AUTOSAR XML (schema 4-2-2)
package /ComponentTypes
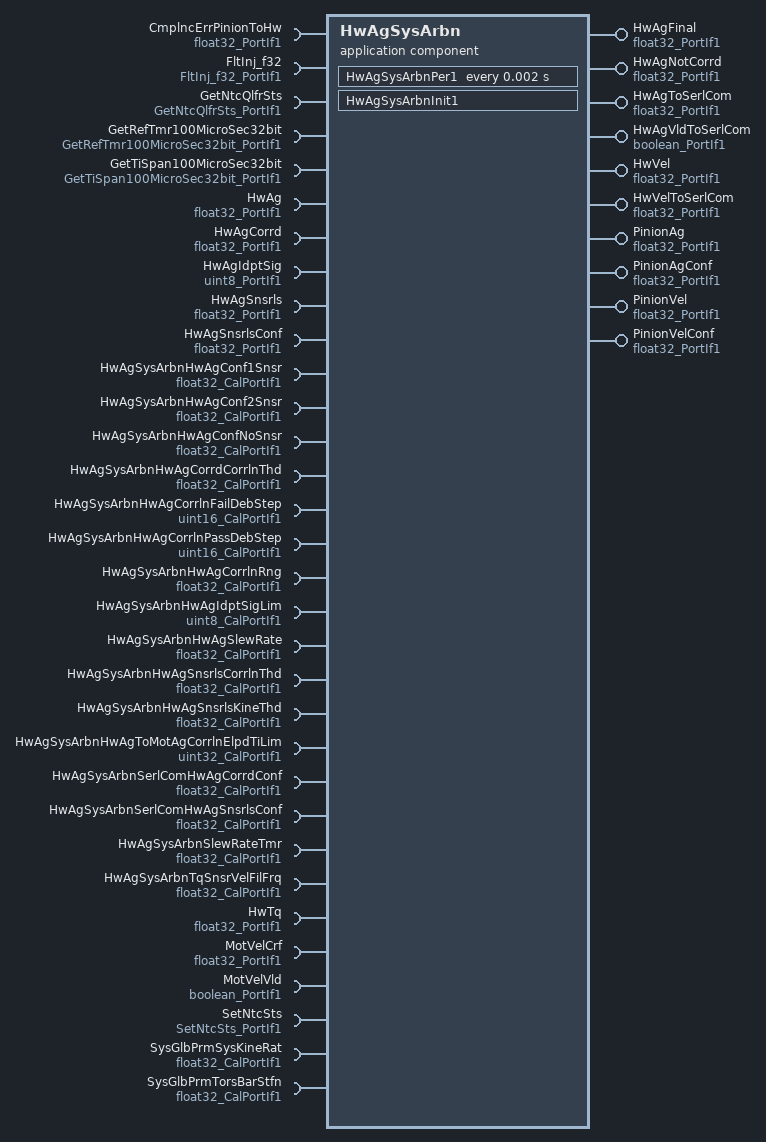
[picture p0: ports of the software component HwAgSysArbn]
  application sw component type HwAgSysArbn
    10 x provide port:
      HwAgFinal: nonqueued-sender-com-spec{data-element=Val, init-value=0}, provided-interface=float32_PortIf1
      HwAgNotCorrd: nonqueued-sender-com-spec{data-element=Val, init-value=0}, provided-interface=float32_PortIf1
      HwAgToSerlCom: nonqueued-sender-com-spec{data-element=Val, init-value=0}, provided-interface=float32_PortIf1
      HwAgVldToSerlCom: nonqueued-sender-com-spec{data-element=Logl, init-value=0}, provided-interface=boolean_PortIf1
      HwVel: nonqueued-sender-com-spec{data-element=Val, init-value=0}, provided-interface=float32_PortIf1
      HwVelToSerlCom: nonqueued-sender-com-spec{data-element=Val, init-value=0}, provided-interface=float32_PortIf1
      PinionAg: nonqueued-sender-com-spec{data-element=Val, init-value=0}, provided-interface=float32_PortIf1
      PinionAgConf: nonqueued-sender-com-spec{data-element=Val, init-value=0}, provided-interface=float32_PortIf1
      PinionVel: nonqueued-sender-com-spec{data-element=Val, init-value=0}, provided-interface=float32_PortIf1
      PinionVelConf: nonqueued-sender-com-spec{data-element=Val, init-value=0}, provided-interface=float32_PortIf1
    32 x require port:
      CmplncErrPinionToHw: nonqueued-receiver-com-spec{data-element=Val, filter=data-filter-type=ALWAYS, init-value=0}, required-interface=float32_PortIf1
      FltInj_f32: client-com-spec=Oper, required-interface=FltInj_f32_PortIf1
      GetNtcQlfrSts: client-com-spec=Oper, required-interface=GetNtcQlfrSts_PortIf1
      GetRefTmr100MicroSec32bit: client-com-spec=Oper, required-interface=GetRefTmr100MicroSec32bit_PortIf1
      GetTiSpan100MicroSec32bit: client-com-spec=Oper, required-interface=GetTiSpan100MicroSec32bit_PortIf1
      HwAg: nonqueued-receiver-com-spec{data-element=Val, filter=data-filter-type=ALWAYS, init-value=0}, required-interface=float32_PortIf1
      HwAgCorrd: nonqueued-receiver-com-spec{data-element=Val, filter=data-filter-type=ALWAYS, init-value=0}, required-interface=float32_PortIf1
      HwAgIdptSig: nonqueued-receiver-com-spec{data-element=Val, filter=data-filter-type=ALWAYS, init-value=2}, required-interface=uint8_PortIf1
      HwAgSnsrls: nonqueued-receiver-com-spec{data-element=Val, filter=data-filter-type=ALWAYS, init-value=0}, required-interface=float32_PortIf1
      HwAgSnsrlsConf: nonqueued-receiver-com-spec{data-element=Val, filter=data-filter-type=ALWAYS, init-value=0}, required-interface=float32_PortIf1
      HwAgSysArbnHwAgConf1Snsr: parameter-require-com-spec{init-value=1, parameter=Val}, required-interface=float32_CalPortIf1
      HwAgSysArbnHwAgConf2Snsr: parameter-require-com-spec{init-value=1, parameter=Val}, required-interface=float32_CalPortIf1
      HwAgSysArbnHwAgConfNoSnsr: parameter-require-com-spec{init-value=0, parameter=Val}, required-interface=float32_CalPortIf1
      HwAgSysArbnHwAgCorrdCorrlnThd: parameter-require-com-spec{init-value=1, parameter=Val}, required-interface=float32_CalPortIf1
      HwAgSysArbnHwAgCorrlnFailDebStep: parameter-require-com-spec{init-value=132, parameter=Val}, required-interface=uint16_CalPortIf1
      HwAgSysArbnHwAgCorrlnPassDebStep: parameter-require-com-spec{init-value=132, parameter=Val}, required-interface=uint16_CalPortIf1
      HwAgSysArbnHwAgCorrlnRng: parameter-require-com-spec{init-value=5, parameter=Val}, required-interface=float32_CalPortIf1
      HwAgSysArbnHwAgIdptSigLim: parameter-require-com-spec{init-value=1, parameter=Val}, required-interface=uint8_CalPortIf1
      HwAgSysArbnHwAgSlewRate: parameter-require-com-spec{init-value=100, parameter=Val}, required-interface=float32_CalPortIf1
      HwAgSysArbnHwAgSnsrlsCorrlnThd: parameter-require-com-spec{init-value=1, parameter=Val}, required-interface=float32_CalPortIf1
      HwAgSysArbnHwAgSnsrlsKineThd: parameter-require-com-spec{init-value=1500, parameter=Val}, required-interface=float32_CalPortIf1
      HwAgSysArbnHwAgToMotAgCorrlnElpdTiLim: parameter-require-com-spec{init-value=86400, parameter=Val}, required-interface=uint32_CalPortIf1
      HwAgSysArbnSerlComHwAgCorrdConf: parameter-require-com-spec{init-value=1, parameter=Val}, required-interface=float32_CalPortIf1
      HwAgSysArbnSerlComHwAgSnsrlsConf: parameter-require-com-spec{init-value=1, parameter=Val}, required-interface=float32_CalPortIf1
      HwAgSysArbnSlewRateTmr: parameter-require-com-spec{init-value=1000, parameter=Val}, required-interface=float32_CalPortIf1
      HwAgSysArbnTqSnsrVelFilFrq: parameter-require-com-spec{init-value=20, parameter=Val}, required-interface=float32_CalPortIf1
      HwTq: nonqueued-receiver-com-spec{data-element=Val, filter=data-filter-type=ALWAYS, init-value=0}, required-interface=float32_PortIf1
      MotVelCrf: nonqueued-receiver-com-spec{data-element=Val, filter=data-filter-type=ALWAYS, init-value=0}, required-interface=float32_PortIf1
      MotVelVld: nonqueued-receiver-com-spec{data-element=Logl, filter=data-filter-type=ALWAYS, init-value=0}, required-interface=boolean_PortIf1
      SetNtcSts: client-com-spec=Oper, required-interface=SetNtcSts_PortIf1
      SysGlbPrmSysKineRat: parameter-require-com-spec{init-value=22, parameter=Val}, required-interface=float32_CalPortIf1
      SysGlbPrmTorsBarStfn: parameter-require-com-spec{init-value=2.5, parameter=Val}, required-interface=float32_CalPortIf1
    behavior HwAgSysArbn_InternalBehavior
      ar-typed-per-instance-memorys:
        14 x data, all with sw-calibration-access=READ-ONLY:
          HwAgKineFlt: type=boolean
          HwAgLtch: type=boolean
          HwAgPrev: type=float32
          HwAgToMotAgCorrln: type=boolean
          HwAgToMotAgCorrlnDurnRefTmr: type=uint32
          PrevHwAgNotCorrd: type=float32
          PrevPinionAgConf: type=float32
          PrevSeldHwAg: type=float32
          PrevSrcSeln: type=sint8
          SeldHwAgConf: type=float32
          SlewElpdRefTmr: type=uint32
          SlewSts: type=boolean
          TqSnsrAgPrev: type=float32
          TqSnsrVelFil: type=FilLpRec1
      init event HwAg0Conf_InitEvent: start-on-event=HwAgSysArbnInit1
      timing event TMT_HwAgSysArbnPer1: start-on-event=HwAgSysArbnPer1, period=0.002
      runnable HwAgSysArbnInit1
        sync call SC_GetRefTmr100MicroSec32bit_Oper: operation=GetRefTmr100MicroSec32bit.Oper, timeout=0
        sync call SC_SetNtcSts_Oper: operation=SetNtcSts.Oper, timeout=0
      runnable HwAgSysArbnPer1
        data-receive-point-by-arguments:
          9 x access:
            REC_CmplncErrPinionToHw_Val: accessed-variable=CmplncErrPinionToHw.Val
            REC_HwAg0Conf_Val: accessed-variable=HwAgCorrd.Val
            REC_HwAg0IdptSig_Val: accessed-variable=HwAgIdptSig.Val
            REC_HwAg1Conf_Val: accessed-variable=HwAgSnsrlsConf.Val
            REC_HwAgSig0_Val: accessed-variable=HwAgSnsrls.Val
            REC_HwAgSig1_Val: accessed-variable=HwAg.Val
            REC_HwTq_Val: accessed-variable=HwTq.Val
            REC_MotVelCrf_Val: accessed-variable=MotVelCrf.Val
            REC_MotVelVld_Logl: accessed-variable=MotVelVld.Logl
        data-send-points:
          10 x access:
            SEND_HwAgFinal_Val: accessed-variable=HwAgFinal.Val
            SEND_HwAgNotCorrd_Val: accessed-variable=HwAgNotCorrd.Val
            SEND_HwAgStsToSerlCom_Logl: accessed-variable=HwAgVldToSerlCom.Logl
            SEND_HwAgToSerlCom_Val: accessed-variable=HwAgToSerlCom.Val
            SEND_HwVel_Val: accessed-variable=HwVel.Val
            SEND_HwVelToSerlCom_Val: accessed-variable=HwVelToSerlCom.Val
            SEND_PinionAg_Val: accessed-variable=PinionAg.Val
            SEND_PinionAgConf_Val: accessed-variable=PinionAgConf.Val
            SEND_PinionVel_Val: accessed-variable=PinionVel.Val
            SEND_PinionVelConf_Val: accessed-variable=PinionVelConf.Val
        5 x sync call, all with timeout=0:
          SC_FltInj_f32_Oper: operation=FltInj_f32.Oper
          SC_GetNtcQlfrSts_Oper: operation=GetNtcQlfrSts.Oper
          SC_GetRefTmr100MicroSec32bit_Oper: operation=GetRefTmr100MicroSec32bit.Oper
          SC_GetTiSpan100MicroSec32bit_Oper: operation=GetTiSpan100MicroSec32bit.Oper
          SC_SetNtcSts_Oper: operation=SetNtcSts.Oper
  swc implementation HwAgSysArbn_Implementation: behavior=HwAgSysArbn_InternalBehavior
    code-descriptors:
      code Default: artifact-descriptors=autosar-engineering-object={short-label=Default, category=SWSRC}
